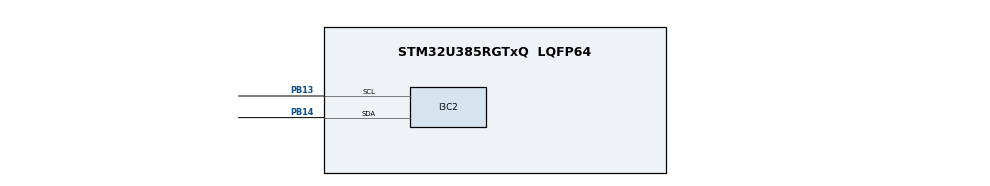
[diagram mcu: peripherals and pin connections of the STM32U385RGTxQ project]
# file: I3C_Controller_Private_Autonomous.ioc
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CORTEX_M33_NS.userName=CORTEX_M33
GPDMA1.DESTDATAWIDTH_GPDMACH0=DMA_DEST_DATAWIDTH_WORD
GPDMA1.DESTINC_GPDMACH1=DMA_DINC_INCREMENTED
GPDMA1.DIRECTION_GPDMACH2=DMA_MEMORY_TO_PERIPH
GPDMA1.IPHANDLE_GPDMACH0-SIMPLEREQUEST_GPDMACH0=__NULL
GPDMA1.IPHANDLE_GPDMACH1-SIMPLEREQUEST_GPDMACH1=__NULL
GPDMA1.IPHANDLE_GPDMACH2-SIMPLEREQUEST_GPDMACH2=__NULL
GPDMA1.REQUEST_GPDMACH0=GPDMA1_REQUEST_I3C2_TC
GPDMA1.REQUEST_GPDMACH1=GPDMA1_REQUEST_I3C2_RX
GPDMA1.REQUEST_GPDMACH2=GPDMA1_REQUEST_I3C2_TX
GPDMA1.SRCDATAWIDTH_GPDMACH0=DMA_SRC_DATAWIDTH_WORD
GPDMA1.SRCINC_GPDMACH0=DMA_SINC_INCREMENTED
GPDMA1.SRCINC_GPDMACH2=DMA_SINC_INCREMENTED
I3C2.AutonomousMode=AUTONOMOUS_MODE_ENABLE
I3C2.BusFreeDuration=432
I3C2.DutyCycleI3C=50
I3C2.FrequencyI3C=12500
I3C2.RXFIFOThreshold=HAL_I3C_RXFIFO_THRESHOLD_1_4
I3C2.Register0=0x00230303
I3C2.Register1=0x0013005e
I3C2.SCLI3CHighDuration=0x03
I3C2.SCLODLowDuration=0x23
I3C2.SCLPPLowDuration=0x03
I3C2.SCL_OD_Freq=2400
I3C2.SCL_PP_Freq=12000
I3C2.TXFIFOThreshold=HAL_I3C_TXFIFO_THRESHOLD_1_4
I3C2.TriggerSelection=I3C_GRP1_RTC_ALRA_TRG
I3C2.hexBusFreeDuration=0x13
I3C2.hexBusIdleDuration=0x5e
Mcu.Family=STM32U3
Mcu.Name=STM32U385RGTxQ
Mcu.Package=LQFP64
NVIC.GPDMA1_Channel0_IRQn=true\:0\:0\:false\:false\:true\:false\:true\:true
NVIC.GPDMA1_Channel1_IRQn=true\:0\:0\:false\:false\:true\:false\:true\:true
NVIC.GPDMA1_Channel2_IRQn=true\:0\:0\:false\:false\:true\:false\:true\:true
NVIC.I3C2_ER_IRQn=true\:0\:0\:false\:false\:true\:true\:true\:true
NVIC.I3C2_EV_IRQn=true\:0\:0\:false\:false\:true\:true\:true\:true
NVIC.PriorityGroup=NVIC_PRIORITYGROUP_4
PB13.Mode=Controller
PB13.Signal=I3C2_SCL
PB14.Mode=Controller
PB14.Signal=I3C2_SDA
ProjectManager.HeapSize=0x200
ProjectManager.StackSize=0x400
ProjectManager.TargetToolchain=EWARM V9.20
RCC.ADCFreq_Value=96000000
RCC.AHBFreq_Value=96000000
RCC.APB1Freq_Value=96000000
RCC.APB1TimFreq_Value=96000000
RCC.APB2Freq_Value=96000000
RCC.APB2TimFreq_Value=96000000
RCC.APB3Freq_Value=96000000
RCC.CortexFreq_Value=12000000
RCC.HCLKFreq_Value=96000000
RCC.HSE_VALUE=16000000
RCC.HSI48_VALUE=48000000
RCC.HSI_VALUE=16000000
RCC.I3C2CLockSelection=RCC_I3C2CLKSOURCE_MSIK
RCC.LSE_VALUE=32768
RCC.LSIDIV_VALUE=32000
RCC.MSISDIV=RCC_MSI_DIV1
RCC.SYSCLKFreq_VALUE=96000000
RCC.USBFreq_Value=96000000
RTC.Alarm-Alarm\ A=RTC_ALARM_A
RTC.AlarmDateWeekDaySel-Alarm\ A=RTC_ALARMDATEWEEKDAYSEL_WEEKDAY
RTC.AsynchPrediv=0x7F
RTC.BinMode=RTC_BINARY_NONE
RTC.Date=14
RTC.Hours=2
RTC.Hours_A-Alarm\ A=2
RTC.Minutes=20
RTC.Minutes_A-Alarm\ A=20
RTC.Month=RTC_MONTH_FEBRUARY
RTC.Seconds_A-Alarm\ A=5
RTC.SubSeconds_A-Alarm\ A=56
RTC.SynchPrediv=0x0F9
RTC.Year=23
VP_GPDMA1_VS_GPDMACH0.Mode=SIMPLEREQUEST_GPDMACH0
VP_GPDMA1_VS_GPDMACH1.Mode=SIMPLEREQUEST_GPDMACH1
VP_GPDMA1_VS_GPDMACH2.Mode=SIMPLEREQUEST_GPDMACH2
VP_ICACHE_VS_ICACHE.Mode=DirectMappedCache
VP_MEMORYMAP_VS_MEMORYMAP.Mode=CurAppReg
VP_PWR_VS_DBSignals.Mode=DisableDeadBatterySignals
VP_PWR_VS_LPOM.Mode=PowerOptimisation
VP_PWR_VS_SECSignals.Mode=Security/Privilege
VP_RTC_VS_RTC_Activate.Mode=RTC_Enabled
VP_RTC_VS_RTC_Alarm_A_Intern.Mode=Alarm A
VP_RTC_VS_RTC_Calendar.Mode=RTC_Calendar
board=custom

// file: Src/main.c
/* USER CODE BEGIN Header */
/**
  ******************************************************************************
  * @file           : I3C/I3C_Controller_Private_Autonomous/Src/main.c
  * @brief          : This sample code shows how to use STM32U3xx I3C HAL API
  *                   as Controller to transmit private message, using autonomous mode.
  *                   The communication is done using 2 Boards.
  ******************************************************************************
  * @attention
  *
  * Copyright (c) 2024 STMicroelectronics.
  * All rights reserved.
  *
  * This software is licensed under terms that can be found in the LICENSE file
  * in the root directory of this software component.
  * If no LICENSE file comes with this software, it is provided AS-IS.
  *
  ******************************************************************************
  */
/* USER CODE END Header */
#include "main.h"

/* USER CODE BEGIN Includes */
#include "desc_target1.h"

/* USER CODE END Includes */

/* USER CODE BEGIN PD */
#define I3C_IDX_FRAME_1         0U  /* Index of Frame 1 */
/* USER CODE END PD */

I3C_HandleTypeDef hi3c2;
DMA_HandleTypeDef handle_GPDMA1_Channel2;
DMA_HandleTypeDef handle_GPDMA1_Channel1;
DMA_HandleTypeDef handle_GPDMA1_Channel0;

RTC_HandleTypeDef hrtc;

/* USER CODE BEGIN PV */
/* Context buffer related to Frame context, contain different buffer value for a communication */
I3C_XferTypeDef aContextBuffers[2];

/* USER CODE BEGIN PV */
/* Number of Targets detected during DAA procedure */
__IO uint32_t uwTargetCount = 0;

/* Buffer used for transmission */
uint8_t aTxBuffer[] = " ****I3C_TwoBoards communication based on IT****  ****I3C_TwoBoards communication based on IT****  ****I3C_TwoBoards communication based on IT**** ";

/* Buffer used for reception */
uint8_t aRxBuffer[RXBUFFERSIZE];

/* Buffer used by HAL to compute control data for the Private Communication */
uint32_t aControlBuffer[0xF];

/* Array contain targets descriptor */
TargetDesc_TypeDef *aTargetDesc[1] = \
                          {
                            &TargetDesc1       /* DEVICE_ID1 */
                          };

/* Descriptor for private data transmit */
I3C_PrivateTypeDef aPrivateDescriptor[1] = \
                                          {
                                            {TARGET1_DYN_ADDR, {aTxBuffer, TXBUFFERSIZE}, {NULL, 0}, HAL_I3C_DIRECTION_WRITE}
                                          };

/* Buffer that contain payload data, mean PID, BCR, DCR */
uint8_t aPayloadBuffer[64*COUNTOF(aTargetDesc)];

/* USER CODE END PV */

void SystemClock_Config(void);
static void MX_GPIO_Init(void);
static void MX_GPDMA1_Init(void);
static void MX_I3C2_Init(void);
static void MX_ICACHE_Init(void);
static void MX_RTC_Init(void);

int main(void)
{

  /* MCU Configuration--------------------------------------------------------*/

  /* Reset of all peripherals, Initializes the Flash interface and the Systick. */
  HAL_Init();

  /* USER CODE BEGIN Init */
  HAL_PWR_EnableBkUpAccess();
  /* USER CODE END Init */

  /* Configure the system clock */
  SystemClock_Config();

  /* Initialize all configured peripherals */
  MX_GPIO_Init();
  MX_GPDMA1_Init();
  MX_I3C2_Init();
  MX_ICACHE_Init();
  /* USER CODE BEGIN 2 */

  /* Configure LD2 */
  BSP_LED_Init(LD2);

  /* Configure USER push-button */
  BSP_PB_Init(BUTTON_USER, BUTTON_MODE_GPIO);

  /* Wait for USER push-button press before starting the Communication   */
  while (BSP_PB_GetState(BUTTON_USER) != GPIO_PIN_RESET)
  {
  }

  /* Wait for USER push-button release before starting the Communication */
  while (BSP_PB_GetState(BUTTON_USER) != GPIO_PIN_SET)
  {
  }

  /*##- Start the transmission process ###################################*/
  /* Assign dynamic address processus */
  if (HAL_I3C_Ctrl_DynAddrAssign_IT(&hi3c2, I3C_ONLY_ENTDAA) != HAL_OK)
  {
    /* Error_Handler() function is called when error occurs. */
    Error_Handler();
  }

  /*##- Wait for the end of the transfer #################################*/
  /*  Before starting a new communication transfer, you need to check the current
  state of the peripheral; if it s busy you need to wait for the end of current
  transfer before starting a new one.
  For simplicity reasons, this example is just waiting till the end of the
  transfer, but application may perform other tasks while transfer operation
  is ongoing. */
  while (HAL_I3C_GetState(&hi3c2) != HAL_I3C_STATE_READY)
  {
  }

  /*##- Prepare context buffers process ##################################*/
  /* Prepare Transmit context buffer with the different parameters */
  aContextBuffers[I3C_IDX_FRAME_1].CtrlBuf.pBuffer = aControlBuffer;
  aContextBuffers[I3C_IDX_FRAME_1].CtrlBuf.Size    = 1;
  aContextBuffers[I3C_IDX_FRAME_1].TxBuf.pBuffer   = aTxBuffer;
  aContextBuffers[I3C_IDX_FRAME_1].TxBuf.Size      = TXBUFFERSIZE;

  /*##- Add context buffer transmit in Frame context #####################*/
  if (HAL_I3C_AddDescToFrame(&hi3c2,
                             NULL,
                             &aPrivateDescriptor[I3C_IDX_FRAME_1],
                             &aContextBuffers[I3C_IDX_FRAME_1],
                             aContextBuffers[I3C_IDX_FRAME_1].CtrlBuf.Size,
                             I3C_PRIVATE_WITH_ARB_STOP) != HAL_OK)
  {
    /* Error_Handler() function is called when error occurs. */
    Error_Handler();
  }

  /*##- Start the transmission process ###################################*/
  /* Transmit private data processus */
  if (HAL_I3C_Ctrl_Transmit_DMA(&hi3c2, &aContextBuffers[I3C_IDX_FRAME_1]) != HAL_OK)
  {
    /* Error_Handler() function is called when error occurs. */
    Error_Handler();
  }

  /* Verify that transfer is still in pending/busy state */
  if (HAL_I3C_GetState(&hi3c2) != HAL_I3C_STATE_BUSY_TX)
  {
    /* Error_Handler() function is called when error occurs. */
    Error_Handler();
  }

  /* Disable all I3C and DMA interrupts to prevent wakeup */
  __HAL_I3C_DISABLE_IT(&hi3c2, HAL_I3C_ALL_COMMON_ITS_MASK | HAL_I3C_ALL_CTRL_ITS);
  __HAL_DMA_DISABLE_IT(&handle_GPDMA1_Channel0, DMA_IT_TC | DMA_IT_ULE | DMA_IT_USE);
  __HAL_DMA_DISABLE_IT(&handle_GPDMA1_Channel2, DMA_IT_TC | DMA_IT_ULE | DMA_IT_USE);

  /* Initialize RTC peripheral, and start RTC alarm A */
  MX_RTC_Init();

  /* Suspend Tick increment to prevent wakeup */
  HAL_SuspendTick();

  /* Disable the Debug Module during STOP 0 modes. */
  HAL_DBGMCU_DisableDBGStopMode();

  /* Enter the system in STOP 0 mode */
  HAL_PWR_EnterSTOPMode(PWR_LOWPOWERMODE_STOP0, PWR_STOPENTRY_WFI);

  /* Resume Tick increment */
  HAL_ResumeTick();

  /* USER CODE END 2 */

  /* Infinite loop */
  while (1)
  {

  }
}

void SystemClock_Config(void)
{
  RCC_OscInitTypeDef RCC_OscInitStruct = {0};
  RCC_ClkInitTypeDef RCC_ClkInitStruct = {0};

  /** Configure the System Power Supply
  */
  if (HAL_PWREx_ConfigSupply(PWR_SMPS_SUPPLY) != HAL_OK)
  {
    Error_Handler();
  }

  /** Enable Epod Booster
  */
  if (HAL_RCCEx_EpodBoosterClkConfig(RCC_EPODBOOSTER_SOURCE_MSIS, RCC_EPODBOOSTER_DIV1) != HAL_OK)
  {
    Error_Handler();
  }
  if (HAL_PWREx_EnableEpodBooster() != HAL_OK)
  {
    Error_Handler();
  }

  /** Configure the main internal regulator output voltage
  */
  if (HAL_PWREx_ControlVoltageScaling(PWR_REGULATOR_VOLTAGE_SCALE1) != HAL_OK)
  {
    Error_Handler();
  }

  /** Set Flash latency before increasing MSIS
  */
  __HAL_FLASH_SET_LATENCY(FLASH_LATENCY_2);

  /** Initializes the CPU, AHB and APB buses clocks
  */
  RCC_OscInitStruct.OscillatorType = RCC_OSCILLATORTYPE_LSI|RCC_OSCILLATORTYPE_MSIS
                              |RCC_OSCILLATORTYPE_MSIK;
  RCC_OscInitStruct.LSIState = RCC_LSI_ON;
  RCC_OscInitStruct.LSIDiv = RCC_LSI_DIV1;
  RCC_OscInitStruct.MSISState = RCC_MSI_ON;
  RCC_OscInitStruct.MSISSource = RCC_MSI_RC0;
  RCC_OscInitStruct.MSISDiv = RCC_MSI_DIV1;
  RCC_OscInitStruct.MSIKState = RCC_MSI_ON;
  RCC_OscInitStruct.MSIKSource = RCC_MSI_RC0;
  RCC_OscInitStruct.MSIKDiv = RCC_MSI_DIV1;

  if (HAL_RCC_OscConfig(&RCC_OscInitStruct) != HAL_OK)
  {
    Error_Handler();
  }

  /** Initializes the CPU, AHB and APB buses clocks
  */
  RCC_ClkInitStruct.ClockType = RCC_CLOCKTYPE_HCLK|RCC_CLOCKTYPE_SYSCLK
                              |RCC_CLOCKTYPE_PCLK1|RCC_CLOCKTYPE_PCLK2
                              |RCC_CLOCKTYPE_PCLK3;
  RCC_ClkInitStruct.SYSCLKSource = RCC_SYSCLKSOURCE_MSIS;
  RCC_ClkInitStruct.AHBCLKDivider = RCC_SYSCLK_DIV1;
  RCC_ClkInitStruct.APB1CLKDivider = RCC_HCLK_DIV1;
  RCC_ClkInitStruct.APB2CLKDivider = RCC_HCLK_DIV1;
  RCC_ClkInitStruct.APB3CLKDivider = RCC_HCLK_DIV1;

  if (HAL_RCC_ClockConfig(&RCC_ClkInitStruct, FLASH_LATENCY_2) != HAL_OK)
  {
    Error_Handler();
  }
}

static void MX_GPDMA1_Init(void)
{

  /* Peripheral clock enable */
  __HAL_RCC_GPDMA1_CLK_ENABLE();

  /* GPDMA1 interrupt Init */
    HAL_NVIC_SetPriority(GPDMA1_Channel0_IRQn, 0, 0);
    HAL_NVIC_EnableIRQ(GPDMA1_Channel0_IRQn);
    HAL_NVIC_SetPriority(GPDMA1_Channel1_IRQn, 0, 0);
    HAL_NVIC_EnableIRQ(GPDMA1_Channel1_IRQn);
    HAL_NVIC_SetPriority(GPDMA1_Channel2_IRQn, 0, 0);
    HAL_NVIC_EnableIRQ(GPDMA1_Channel2_IRQn);

}

static void MX_I3C2_Init(void)
{

  I3C_FifoConfTypeDef sFifoConfig = {0};
  I3C_CtrlConfTypeDef sCtrlConfig = {0};
  I3C_AutonomousModeConfTypeDef sConfigI3C2 = {0};

  hi3c2.Instance = I3C2;
  hi3c2.Mode = HAL_I3C_MODE_CONTROLLER;
  hi3c2.Init.CtrlBusCharacteristic.SDAHoldTime = HAL_I3C_SDA_HOLD_TIME_0_5;
  hi3c2.Init.CtrlBusCharacteristic.WaitTime = HAL_I3C_OWN_ACTIVITY_STATE_0;
  hi3c2.Init.CtrlBusCharacteristic.SCLPPLowDuration = 0x03;
  hi3c2.Init.CtrlBusCharacteristic.SCLI3CHighDuration = 0x03;
  hi3c2.Init.CtrlBusCharacteristic.SCLODLowDuration = 0x23;
  hi3c2.Init.CtrlBusCharacteristic.SCLI2CHighDuration = 0x00;
  hi3c2.Init.CtrlBusCharacteristic.BusFreeDuration = 0x13;
  hi3c2.Init.CtrlBusCharacteristic.BusIdleDuration = 0x5e;
  if (HAL_I3C_Init(&hi3c2) != HAL_OK)
  {
    Error_Handler();
  }

  /** Configure FIFO
  */
  sFifoConfig.RxFifoThreshold = HAL_I3C_RXFIFO_THRESHOLD_1_4;
  sFifoConfig.TxFifoThreshold = HAL_I3C_TXFIFO_THRESHOLD_1_4;
  sFifoConfig.ControlFifo = HAL_I3C_CONTROLFIFO_DISABLE;
  sFifoConfig.StatusFifo = HAL_I3C_STATUSFIFO_DISABLE;
  if (HAL_I3C_SetConfigFifo(&hi3c2, &sFifoConfig) != HAL_OK)
  {
    Error_Handler();
  }

  /** Configure controller
  */
  sCtrlConfig.DynamicAddr = 0;
  sCtrlConfig.StallTime = 0x00;
  sCtrlConfig.HotJoinAllowed = DISABLE;
  sCtrlConfig.ACKStallState = DISABLE;
  sCtrlConfig.CCCStallState = DISABLE;
  sCtrlConfig.TxStallState = DISABLE;
  sCtrlConfig.RxStallState = DISABLE;
  sCtrlConfig.HighKeeperSDA = DISABLE;
  if (HAL_I3C_Ctrl_Config(&hi3c2, &sCtrlConfig) != HAL_OK)
  {
    Error_Handler();
  }

  /** Configure Autonomous Mode
  */
  sConfigI3C2.TriggerState = I3C_TRIGGER_ENABLE;
  sConfigI3C2.TriggerSelection = I3C_GRP1_RTC_ALRA_TRG;
  sConfigI3C2.TriggerPolarity = I3C_TRIG_POLARITY_LOW;
  if (HAL_I3C_SetConfigAutonomousMode(&hi3c2, &sConfigI3C2) != HAL_OK)
  {
    Error_Handler();
  }

}

static void MX_ICACHE_Init(void)
{

  /** Enable instruction cache in 1-way (direct mapped cache)
  */
  if (HAL_ICACHE_ConfigAssociativityMode(ICACHE_1WAY) != HAL_OK)
  {
    Error_Handler();
  }
  if (HAL_ICACHE_Enable() != HAL_OK)
  {
    Error_Handler();
  }

}

static void MX_RTC_Init(void)
{

  RTC_PrivilegeStateTypeDef privilegeState = {0};
  RTC_TimeTypeDef sTime = {0};
  RTC_DateTypeDef sDate = {0};
  RTC_AlarmTypeDef sAlarm = {0};

  /** Initialize RTC Only
  */
  hrtc.Instance = RTC;
  hrtc.Init.HourFormat = RTC_HOURFORMAT_24;
  hrtc.Init.AsynchPrediv = 0x7F;
  hrtc.Init.SynchPrediv = 0x0F9;
  hrtc.Init.OutPut = RTC_OUTPUT_DISABLE;
  hrtc.Init.OutPutRemap = RTC_OUTPUT_REMAP_NONE;
  hrtc.Init.OutPutPolarity = RTC_OUTPUT_POLARITY_HIGH;
  hrtc.Init.OutPutType = RTC_OUTPUT_TYPE_OPENDRAIN;
  hrtc.Init.OutPutPullUp = RTC_OUTPUT_PULLUP_NONE;
  hrtc.Init.BinMode = RTC_BINARY_NONE;
  if (HAL_RTC_Init(&hrtc) != HAL_OK)
  {
    Error_Handler();
  }
  privilegeState.rtcPrivilegeFull = RTC_PRIVILEGE_FULL_NO;
  privilegeState.backupRegisterPrivZone = RTC_PRIVILEGE_BKUP_ZONE_NONE;
  privilegeState.backupRegisterStartZone2 = RTC_BKP_DR0;
  privilegeState.backupRegisterStartZone3 = RTC_BKP_DR0;
  if (HAL_RTCEx_PrivilegeModeSet(&hrtc, &privilegeState) != HAL_OK)
  {
    Error_Handler();
  }

  /** Initialize RTC and set the Time and Date
  */
  sTime.Hours = 0x2;
  sTime.Minutes = 0x20;
  sTime.Seconds = 0x0;
  sTime.DayLightSaving = RTC_DAYLIGHTSAVING_NONE;
  sTime.StoreOperation = RTC_STOREOPERATION_RESET;
  if (HAL_RTC_SetTime(&hrtc, &sTime, RTC_FORMAT_BCD) != HAL_OK)
  {
    Error_Handler();
  }
  sDate.WeekDay = RTC_WEEKDAY_MONDAY;
  sDate.Month = RTC_MONTH_FEBRUARY;
  sDate.Date = 0x14;
  sDate.Year = 23;

  if (HAL_RTC_SetDate(&hrtc, &sDate, RTC_FORMAT_BCD) != HAL_OK)
  {
    Error_Handler();
  }

  /** Enable the Alarm A
  */
  sAlarm.AlarmTime.Hours = 0x2;
  sAlarm.AlarmTime.Minutes = 0x20;
  sAlarm.AlarmTime.Seconds = 0x5;
  sAlarm.AlarmTime.SubSeconds = 0x56;
  sAlarm.AlarmMask = RTC_ALARMMASK_NONE;
  sAlarm.AlarmSubSecondMask = RTC_ALARMSUBSECONDMASK_ALL;
  sAlarm.AlarmDateWeekDaySel = RTC_ALARMDATEWEEKDAYSEL_WEEKDAY;
  sAlarm.AlarmDateWeekDay = RTC_WEEKDAY_MONDAY;
  sAlarm.Alarm = RTC_ALARM_A;
  if (HAL_RTC_SetAlarm(&hrtc, &sAlarm, RTC_FORMAT_BCD) != HAL_OK)
  {
    Error_Handler();
  }

}

static void MX_GPIO_Init(void)
{

  /* GPIO Ports Clock Enable */
  __HAL_RCC_GPIOB_CLK_ENABLE();

}

/* USER CODE BEGIN 4 */
/**
  * @brief I3C target request a dynamic address callback.
  *        The main objective of this user function is to check if a target request a dynamic address.
  *        if the case we should assign a dynamic address to the target.
  * @par Called functions
  * - HAL_I3C_TgtReqDynamicAddrCallback()
  * - HAL_I3C_Ctrl_SetDynamicAddress()
  * @retval None
  */
void HAL_I3C_TgtReqDynamicAddrCallback(I3C_HandleTypeDef *hi3c, uint64_t targetPayload)
{
  /* Update Payload on aTargetDesc */
  aTargetDesc[uwTargetCount]->TARGET_BCR_DCR_PID = targetPayload;

  /* Send associated dynamic address */
  HAL_I3C_Ctrl_SetDynAddr(hi3c, aTargetDesc[uwTargetCount++]->DYNAMIC_ADDR);
}

/**
  * @brief  Controller dynamic address assignment Complete callback.
  * @param  hi3c : [IN] Pointer to an I3C_HandleTypeDef structure that contains the configuration information
  *                     for the specified I3C.
  * @retval None
  */
void HAL_I3C_CtrlDAACpltCallback(I3C_HandleTypeDef *hi3c)
{
  /* Turn LD2 on: Transfer in transmission process is correct */
  BSP_LED_On(LD2);
}
/* USER CODE END 4 */

void Error_Handler(void)
{
  /* USER CODE BEGIN Error_Handler_Debug */
  /* Error if LD2 is slowly blinking (1 sec. period) */
  while (1)
  {
    BSP_LED_Toggle(LD2);
    HAL_Delay(1000);
  }
  /* USER CODE END Error_Handler_Debug */
}
